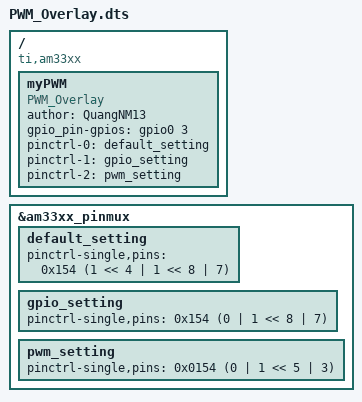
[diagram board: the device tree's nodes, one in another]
/dts-v1/;
/plugin/;
/*
LED5  ---------------------- GPIO0_03       GPIO_03     P9_21       PWM0B
*/

/{
    compatible = "ti,am33xx";
    fragment@0 {
            target = <&am33xx_pinmux>;
            __overlay__ {
                default_setting: default_setting {
                    pinctrl-single,pins = <
                        0x154 (1 << 4 | 1 << 8 | 7)
                    >;
                };

                gpio_setting: gpio_setting {
                    pinctrl-single,pins = <
                        0x154 (0 | 1 << 8 | 7)
                    >;
                };

                pwm_setting: pwm_setting {
                    pinctrl-single,pins = <
                        0x0154 (0 | 1 << 5 | 3)
                    >;
                };
            };
    };

    fragment@1 {
        target-path = "/";
        __overlay__ {
            myPWM {
                compatible = "PWM_Overlay";
                author = "QuangNM13";
                status = "okay";
                gpio_pin-gpios = <&gpio0 3 0>;
                pinctrl-names = "default", "gpio", "pwm";
		        pinctrl-0 = <&default_setting>;
		        pinctrl-1 = <&gpio_setting>;
                pinctrl-2 = <&pwm_setting>;
            };
        }; 
    };
};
